# haltium_cellrf register map
Vendor: Nordic Semiconductor; Series: nRFHaltium; File version: 1
CPU: CM0 r0p0, little endian, no MPU, no FPU, 2 interrupt priority bits, 33 interrupts
Registers are 32-bit, read-write, reset 0x0 unless marked. A register's access mark holds for its fields unless they carry their own. Offsets are from the block's base; [hi:lo] are bit positions; 'fields as' and 'values as' point back to an identical list.

## RFCORESERVICES — RF Core Services used by blocks in AhmaRfSubSystem Core
Base 0x46009000
0x00 TASKS_WARMBOOT wo — Cortex-M0 Warm Boot IRQ
  [0] TASKS_WARMBOOT
    1=Trigger task
0x04 TASKS_DEBUGBOOT wo — Cortex-M0 Debug Boot IRQ
  [0] TASKS_DEBUGBOOT
    1=Trigger task
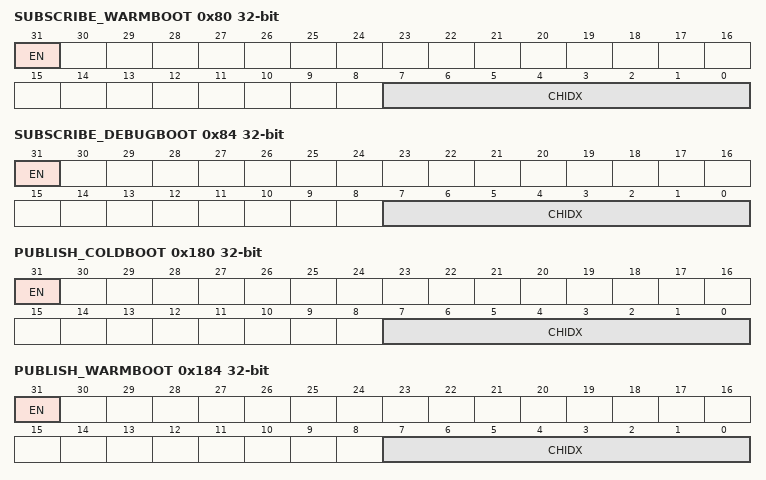
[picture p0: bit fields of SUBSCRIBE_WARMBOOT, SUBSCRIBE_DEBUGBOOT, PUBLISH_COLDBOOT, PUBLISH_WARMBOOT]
0x80 SUBSCRIBE_WARMBOOT — Subscribe configuration for task WARMBOOT
  [31] EN
    0=Disabled (Disable subscription); 1=Enabled (Enable subscription)
  [7:0] CHIDX — DPPI channel that task WARMBOOT will subscribe to
0x84 SUBSCRIBE_DEBUGBOOT — Subscribe configuration for task DEBUGBOOT
  [31] EN
    values as SUBSCRIBE_WARMBOOT.EN
  [7:0] CHIDX — DPPI channel that task DEBUGBOOT will subscribe to
0x100 EVENTS_COLDBOOT — Cortex-M0 Cold Boot IRQ
  [0] EVENTS_COLDBOOT
    0=NotGenerated (Event not generated); 1=Generated (Event generated)
0x104 EVENTS_WARMBOOT — Cortex-M0 Warm Boot IRQ
  [0] EVENTS_WARMBOOT
    values as EVENTS_COLDBOOT.EVENTS_COLDBOOT
0x108 EVENTS_DEBUGBOOT — Cortex-M0 Warm Boot IRQ
  [0] EVENTS_DEBUGBOOT
    values as EVENTS_COLDBOOT.EVENTS_COLDBOOT
0x180 PUBLISH_COLDBOOT — Publish configuration for event COLDBOOT
  [31] EN
    0=Disabled (Disable publishing); 1=Enabled (Enable publishing)
  [7:0] CHIDX — DPPI channel that event COLDBOOT will publish to
0x184 PUBLISH_WARMBOOT — Publish configuration for event WARMBOOT
  [31] EN
    values as PUBLISH_COLDBOOT.EN
  [7:0] CHIDX — DPPI channel that event WARMBOOT will publish to
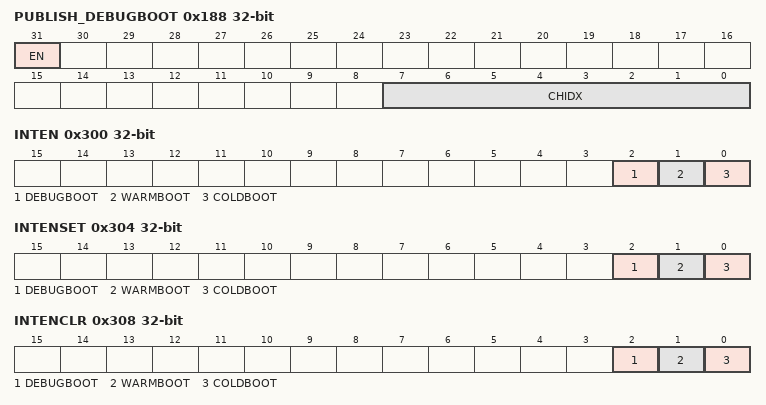
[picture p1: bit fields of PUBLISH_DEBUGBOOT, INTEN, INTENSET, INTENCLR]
0x188 PUBLISH_DEBUGBOOT — Publish configuration for event DEBUGBOOT
  [31] EN
    values as PUBLISH_COLDBOOT.EN
  [7:0] CHIDX — DPPI channel that event DEBUGBOOT will publish to
0x300 INTEN — Enable or disable interrupt
  [all] fields
    0=Disabled; 1=Enabled
  [2] DEBUGBOOT — Enable or disable interrupt for event DEBUGBOOT
  [1] WARMBOOT — Enable or disable interrupt for event WARMBOOT
  [0] COLDBOOT — Enable or disable interrupt for event COLDBOOT
0x304 INTENSET — Enable interrupt
  [all] fields
    on read: 0=Disabled (Read: Disabled); 1=Enabled (Read: Enabled) | on write: 1=Set (Enable)
  [2] DEBUGBOOT — Write '1' to enable interrupt for event DEBUGBOOT
  [1] WARMBOOT — Write '1' to enable interrupt for event WARMBOOT
  [0] COLDBOOT — Write '1' to enable interrupt for event COLDBOOT
0x308 INTENCLR — Disable interrupt
  [all] fields
    on read: 0=Disabled (Read: Disabled); 1=Enabled (Read: Enabled) | on write: 1=Clear (Disable)
  [2] DEBUGBOOT — Write '1' to disable interrupt for event DEBUGBOOT
  [1] WARMBOOT — Write '1' to disable interrupt for event WARMBOOT
  [0] COLDBOOT — Write '1' to disable interrupt for event COLDBOOT
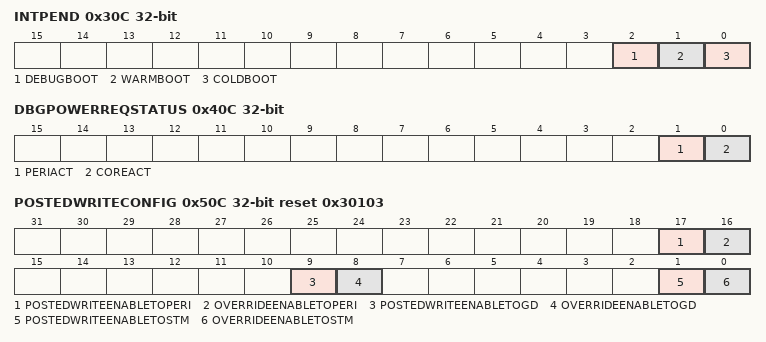
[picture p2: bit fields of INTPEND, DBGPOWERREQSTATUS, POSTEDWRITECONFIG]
0x30C INTPEND ro — Pending interrupts
  [all] fields
    on read: 0=NotPending (Read: Not pending); 1=Pending (Read: Pending)
  [2] DEBUGBOOT — Read pending status of interrupt for event DEBUGBOOT
  [1] WARMBOOT — Read pending status of interrupt for event WARMBOOT
  [0] COLDBOOT — Read pending status of interrupt for event COLDBOOT
0x400 CKREQSTATUS ro reset 0x82008 — Clock request status
  [9:0] CKREQSTATUS — Clock request status for each peripheral in AhmaRf Core
0x404 CPUID ro reset 0x6 — AhmaRf Cortex-M0 CPU ID
  [31:0] CPUID — AhmaRf Cortex-M0 system-wide CPU ID
0x408 ISOLATEPERISTATUS ro reset 0x1 — PERI_ACT power domain isolation status
  [0] ISOLATEPERITOP
0x40C DBGPOWERREQSTATUS ro — PERI_ACT power domain isolation status
  [1] PERIACT — Status of signal dbgPdReqAhmaRf_CoreAct. It is a debug power request for PD_PERI from Trace and Debug system
  [0] COREACT — Status of signal dbgPdReqAhmaRf_CoreAct. It is a debug power request for PD_CORE from Trace and Debug system
0x504 DELAYREGCONFIG — Delay Register Configuration Register
  [4:0] DELAY — Number of wait states to introduce on transfers to/from the DELAYREG register
0x508 POWERCLOCKMODE — Power and clock mode
  [1:0] POWERCLOCKMODE — Peripheral domain power and clock mode
    0=Power_Off (Peripheral domain is allowed to power off); 1=Clocks_Off (Peripheral domain is not allowed to power off, but is allowed to turn its clocks off); 2=Clocks_Gated (Peripheral domain is not allowed to power off, and its clock generators are kept running while the clocks themselves may be gated); 3=All_On (Peripheral domain is forced to have its clocks running)
0x50C POSTEDWRITECONFIG reset 0x30103 — Posted write configuration for CM0
  [17] POSTEDWRITEENABLETOPERI — Override value for writes to AhmaRfPeri (only used when OVERRIDEENABLETOPERI is Forced)
    0=ForceNonPosted (Writes to AhmaRfPeri are performed using non-posted writes); 1=ForcePosted (Writes to AhmaRfPeri are performed using posted writes)
  [16] OVERRIDEENABLETOPERI — Override enable for writes to AhmaRfPeri
    0=NotForced (Writes to AhmaRfPeri are performed as specified by CM0); 1=Forced (Writes to AhmaRfPeri are forced to be either posted or non-posted based on POSTEDWRITEENABLETOPERI)
  [9] POSTEDWRITEENABLETOGD — Override value for writes to the GD_UP bus (other than STM; only used when OVERRIDEENABLETOGD is Forced)
    0=ForceNonPosted (Writes to GD_UP are performed using non-posted writes); 1=ForcePosted (Writes to GD_UP are performed using posted writes)
  [8] OVERRIDEENABLETOGD — Override enable for writes to the GD_UP bus (other than STM)
    0=NotForced (Writes to GD_UP are performed as specified by CM0); 1=Forced (Writes to GD_UP are forced to be either posted or non-posted based on POSTEDWRITEENABLETOGD)
  [1] POSTEDWRITEENABLETOSTM — Override value for writes to STM (only used when OVERRIDEENABLETOSTM is Forced)
    0=ForceNonPosted (Writes to STM are performed using non-posted writes); 1=ForcePosted (Writes to STM are performed using posted writes)
  [0] OVERRIDEENABLETOSTM — Override enable for writes to STM
    0=NotForced (Writes to STM are performed as specified by CM0); 1=Forced (Writes to STM are forced to be either posted or non-posted based on POSTEDWRITEENABLETOSTM)
0x600 DELAYREG — Delay Register
  [31:0] REG — General-purpose register that produces a number of wait states on the bus (see DELAYREGCONFIG)
